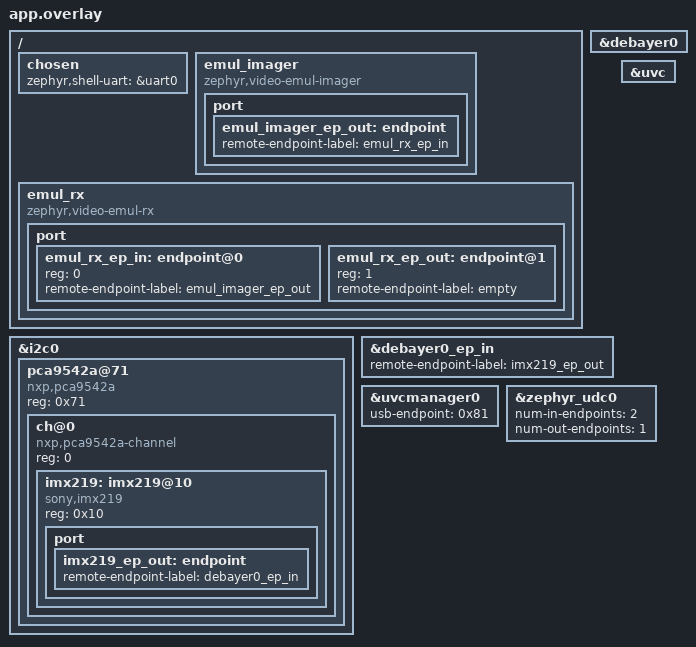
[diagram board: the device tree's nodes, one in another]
/*
 * Copyright (c) 2024 tinyVision.ai Inc.
 *
 * SPDX-License-Identifier: Apache-2.0
 */

/ {
	chosen {
		zephyr,shell-uart = &uart0;
	};

	emul_imager {
		compatible = "zephyr,video-emul-imager";

		port {
			emul_imager_ep_out: endpoint {
				remote-endpoint-label = "emul_rx_ep_in";
			};
		};
	};

	emul_rx {
		compatible = "zephyr,video-emul-rx";

		port {
			#address-cells = <1>;
			#size-cells = <0>;

			emul_rx_ep_in: endpoint@0 {
				reg = <0>;
				remote-endpoint-label = "emul_imager_ep_out";
			};

			emul_rx_ep_out: endpoint@1 {
				reg = <1>;
				remote-endpoint-label = "empty";
			};
		};
	};
};

&i2c0 {
	status = "okay";

	pca9542a@71 {
		compatible = "nxp,pca9542a";
		reg = <0x71>;
		#address-cells = <1>;
		#size-cells = <0>;

		ch@0 {
			compatible = "nxp,pca9542a-channel";
			reg = <0>;
			#address-cells = <1>;
			#size-cells = <0>;

			imx219: imx219@10 {
				compatible = "sony,imx219";
				reg = <0x10>;

				port {
					imx219_ep_out: endpoint {
						remote-endpoint-label = "debayer0_ep_in";
					};
				};
			};
		};
	};
};

&debayer0 {
	status = "okay";
};

&debayer0_ep_in {
	remote-endpoint-label = "imx219_ep_out";
};

&uvcmanager0 {
	status = "okay";

	/* From UVC's "bEndpointAddress" in "lsusb -v -d 1209:0001" output */
	usb-endpoint = <0x81>;
};

&uvc {
	status = "okay";
};

&zephyr_udc0 {
	num-in-endpoints = <2>;
	num-out-endpoints = <1>;
	status = "okay";
};
